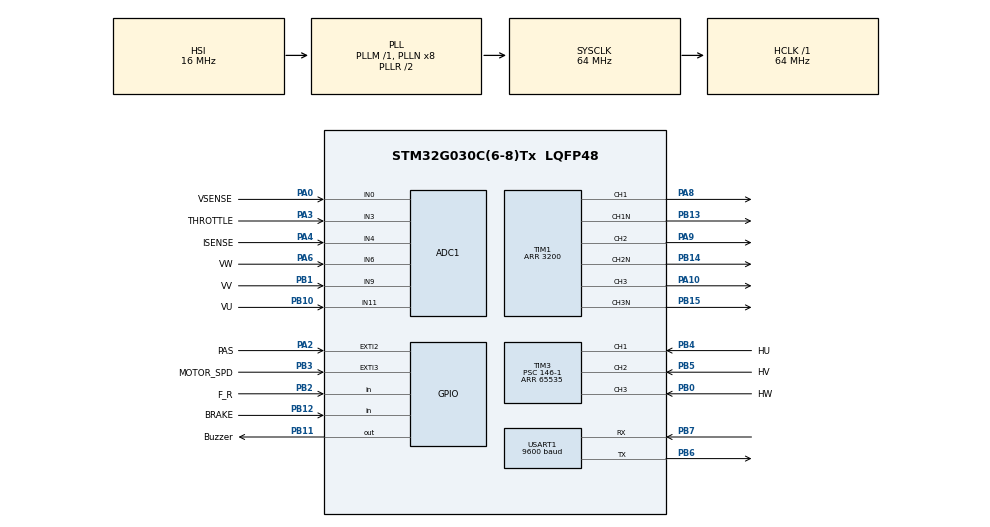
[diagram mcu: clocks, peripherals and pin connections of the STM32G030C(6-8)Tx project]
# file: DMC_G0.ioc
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ADC1.Channel-2\#ChannelRegularConversion=ADC_CHANNEL_3
ADC1.Channel-3\#ChannelRegularConversion=ADC_CHANNEL_4
ADC1.Channel-4\#ChannelRegularConversion=ADC_CHANNEL_0
ADC1.Channel-5\#ChannelRegularConversion=ADC_CHANNEL_TEMPSENSOR
ADC1.ContinuousConvMode=ENABLE
ADC1.DMAContinuousRequests=ENABLE
ADC1.NbrOfConversion=4
ADC1.NbrOfConversionFlag=1
ADC1.Rank-2\#ChannelRegularConversion=1
ADC1.Rank-3\#ChannelRegularConversion=2
ADC1.Rank-4\#ChannelRegularConversion=3
ADC1.Rank-5\#ChannelRegularConversion=4
ADC1.SamplingTime-2\#ChannelRegularConversion=ADC_SAMPLINGTIME_COMMON_1
ADC1.SamplingTime-3\#ChannelRegularConversion=ADC_SAMPLINGTIME_COMMON_1
ADC1.SamplingTime-4\#ChannelRegularConversion=ADC_SAMPLINGTIME_COMMON_1
ADC1.SamplingTime-5\#ChannelRegularConversion=ADC_SAMPLINGTIME_COMMON_1
ADC1.SamplingTimeCommon1=ADC_SAMPLETIME_160CYCLES_5
ADC1.SamplingTimeCommon2=ADC_SAMPLETIME_79CYCLES_5
ADC1.SelectedChannel=ADC_CHANNEL_0|ADC_CHANNEL_3|ADC_CHANNEL_4|ADC_CHANNEL_6|ADC_CHANNEL_TEMPSENSOR|ADC_CHANNEL_9|ADC_CHANNEL_11
ADC1.master=1
Dma.ADC1.0.Direction=DMA_PERIPH_TO_MEMORY
Dma.ADC1.0.EventEnable=DISABLE
Dma.ADC1.0.Instance=DMA1_Channel1
Dma.ADC1.0.MemDataAlignment=DMA_MDATAALIGN_WORD
Dma.ADC1.0.MemInc=DMA_MINC_ENABLE
Dma.ADC1.0.Mode=DMA_CIRCULAR
Dma.ADC1.0.PeriphDataAlignment=DMA_PDATAALIGN_WORD
Dma.ADC1.0.PeriphInc=DMA_PINC_DISABLE
Dma.ADC1.0.Polarity=HAL_DMAMUX_REQ_GEN_RISING
Dma.ADC1.0.Priority=DMA_PRIORITY_LOW
Dma.ADC1.0.RequestNumber=1
Dma.ADC1.0.SignalID=NONE
Dma.ADC1.0.SyncEnable=DISABLE
Dma.ADC1.0.SyncPolarity=HAL_DMAMUX_SYNC_NO_EVENT
Dma.ADC1.0.SyncRequestNumber=1
Dma.ADC1.0.SyncSignalID=NONE
Dma.Request0=ADC1
IWDG.Prescaler=IWDG_PRESCALER_256
Mcu.Family=STM32G0
Mcu.Name=STM32G030C(6-8)Tx
Mcu.Package=LQFP48
NVIC.ADC1_IRQn=true\:0\:0\:false\:false\:true\:true\:true\:true
NVIC.DMA1_Channel1_IRQn=true\:0\:0\:false\:false\:true\:false\:true\:true
NVIC.EXTI2_3_IRQn=true\:0\:0\:false\:true\:true\:1\:true\:true\:true
NVIC.TIM14_IRQn=true\:0\:0\:false\:false\:true\:true\:true\:true
NVIC.TIM17_IRQn=true\:0\:0\:false\:false\:true\:true\:true\:true
NVIC.TIM1_BRK_UP_TRG_COM_IRQn=true\:0\:0\:false\:false\:true\:true\:true\:true
NVIC.TIM1_CC_IRQn=true\:0\:0\:false\:false\:true\:true\:true\:true
NVIC.TIM3_IRQn=true\:0\:0\:false\:false\:true\:true\:true\:true
NVIC.USART1_IRQn=true\:0\:0\:false\:false\:true\:true\:true\:true
PA0.GPIO_Label=VSENSE
PA0.Signal=SharedAnalog_PA0
PA10.Signal=S_TIM1_CH3
PA13.Mode=Serial_Wire
PA13.Signal=SYS_SWDIO
PA14-BOOT0.Mode=Serial_Wire
PA14-BOOT0.Signal=SYS_SWCLK
PA2.GPIO_Label=PAS
PA2.Signal=GPXTI2
PA3.GPIO_Label=THROTTLE
PA3.Signal=SharedAnalog_PA3
PA4.GPIO_Label=ISENSE
PA4.Signal=SharedAnalog_PA4
PA6.GPIO_Label=VW
PA6.Signal=SharedAnalog_PA6
PA8.Signal=S_TIM1_CH1
PA9.Signal=S_TIM1_CH2
PB0.GPIO_Label=HW
PB0.Signal=S_TIM3_CH3
PB1.GPIO_Label=VV
PB1.Signal=SharedAnalog_PB1
PB10.GPIO_Label=VU
PB10.Signal=SharedAnalog_PB10
PB11.GPIO_Label=Buzzer
PB11.GPIO_ModeDefaultOutputPP=GPIO_MODE_OUTPUT_PP
PB11.GPIO_PuPd=GPIO_PULLUP
PB11.Signal=GPIO_Output
PB12.GPIO_Label=BRAKE
PB12.Signal=GPIO_Input
PB13.Mode=PWM Generation1 CH1 CH1N
PB13.Signal=TIM1_CH1N
PB14.Mode=PWM Generation2 CH2 CH2N
PB14.Signal=TIM1_CH2N
PB15.Mode=PWM Generation3 CH3 CH3N
PB15.Signal=TIM1_CH3N
PB2.GPIO_Label=F_R
PB2.GPIO_PuPd=GPIO_PULLUP
PB2.Signal=GPIO_Input
PB3.GPIO_Label=MOTOR_SPD
PB3.Signal=GPXTI3
PB4.GPIO_Label=HU
PB4.Signal=S_TIM3_CH1
PB5.GPIO_Label=HV
PB5.Signal=S_TIM3_CH2
PB6.Mode=Asynchronous
PB6.Signal=USART1_TX
PB7.Mode=Asynchronous
PB7.Signal=USART1_RX
PF0-OSC_IN\ (PF0).Mode=HSE-External-Clock-Source
PF0-OSC_IN\ (PF0).Signal=RCC_OSC_IN
ProjectManager.HeapSize=0x200
ProjectManager.StackSize=0x400
ProjectManager.TargetToolchain=STM32CubeIDE
RCC.ADCFreq_Value=64000000
RCC.AHBFreq_Value=64000000
RCC.CortexFreq_Value=64000000
RCC.EXTERNAL_CLOCK_VALUE=12288000
RCC.HCLKFreq_Value=64000000
RCC.HSE_VALUE=8000000
RCC.HSI_VALUE=16000000
RCC.LSE_VALUE=32768
RCC.SYSCLKFreq_VALUE=64000000
RCC.SYSCLKSource=RCC_SYSCLKSOURCE_PLLCLK
RCC.VCOOutputFreq_Value=128000000
SH.S_TIM1_CH1.0=TIM1_CH1,PWM Generation1 CH1 CH1N
SH.S_TIM1_CH2.0=TIM1_CH2,PWM Generation2 CH2 CH2N
SH.S_TIM1_CH3.0=TIM1_CH3,PWM Generation3 CH3 CH3N
SH.S_TIM3_CH1.0=TIM3_CH1,Xored_Inputs_Hall_Sensor_Interface
SH.S_TIM3_CH2.0=TIM3_CH2,Xored_Inputs_Hall_Sensor_Interface
SH.S_TIM3_CH3.0=TIM3_CH3,Xored_Inputs_Hall_Sensor_Interface
SH.SharedAnalog_PA0.0=GPIO_Analog
SH.SharedAnalog_PA0.1=ADC1_IN0,IN0
SH.SharedAnalog_PA3.0=GPIO_Analog
SH.SharedAnalog_PA3.1=ADC1_IN3,IN3
SH.SharedAnalog_PA4.0=GPIO_Analog
SH.SharedAnalog_PA4.1=ADC1_IN4,IN4
SH.SharedAnalog_PA6.0=GPIO_Analog
SH.SharedAnalog_PA6.1=ADC1_IN6,IN6
SH.SharedAnalog_PB1.0=GPIO_Analog
SH.SharedAnalog_PB1.1=ADC1_IN9,IN9
SH.SharedAnalog_PB10.0=GPIO_Analog
SH.SharedAnalog_PB10.1=ADC1_IN11,IN11
TIM1.AutoReloadPreload=TIM_AUTORELOAD_PRELOAD_ENABLE
TIM1.Channel-PWM\ Generation1\ CH1\ CH1N=TIM_CHANNEL_1
TIM1.Channel-PWM\ Generation2\ CH2\ CH2N=TIM_CHANNEL_2
TIM1.Channel-PWM\ Generation3\ CH3\ CH3N=TIM_CHANNEL_3
TIM1.CounterMode=TIM_COUNTERMODE_CENTERALIGNED1
TIM1.DeadTime=130-1
TIM1.OCNPolarity_1=TIM_OCNPOLARITY_LOW
TIM1.OCNPolarity_2=TIM_OCNPOLARITY_LOW
TIM1.OCNPolarity_3=TIM_OCNPOLARITY_LOW
TIM1.OCPolarity_1=TIM_OCPOLARITY_LOW
TIM1.OCPolarity_2=TIM_OCPOLARITY_LOW
TIM1.OCPolarity_3=TIM_OCPOLARITY_LOW
TIM1.Period=3200
TIM14.Period=3200
TIM17.Prescaler=8
TIM3.AutoReloadPreload=TIM_AUTORELOAD_PRELOAD_DISABLE
TIM3.CounterMode=TIM_COUNTERMODE_UP
TIM3.IC1Filter=14
TIM3.Period=65535
TIM3.Prescaler=146-1
USART1.BaudRate=9600
USART1.VirtualMode-Asynchronous=VM_ASYNC
VP_ADC1_TempSens_Input.Mode=IN-TempSens
VP_IWDG_VS_IWDG.Mode=IWDG_Activate
VP_TIM14_VS_ClockSourceINT.Mode=Enable_Timer
VP_TIM17_VS_ClockSourceINT.Mode=Enable_Timer
VP_TIM1_VS_ClockSourceINT.Mode=Internal
VP_TIM3_VS_ClockSourceINT.Mode=Internal
board=custom

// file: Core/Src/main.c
/* USER CODE BEGIN Header */
/**
  ******************************************************************************
  * @file           : main.c
  * @brief          : Main program body
  ******************************************************************************
  * @attention
  *
  * Copyright (c) 2024 STMicroelectronics.
  * All rights reserved.
  *
  * This software is licensed under terms that can be found in the LICENSE file
  * in the root directory of this software component.
  * If no LICENSE file comes with this software, it is provided AS-IS.
  *
  ******************************************************************************
  */
/* USER CODE END Header */
#include "main.h"
#include "adc.h"
#include "dma.h"
#include "iwdg.h"
#include "tim.h"
#include "usart.h"
#include "gpio.h"

/* USER CODE BEGIN Includes */
#include "initialtask.h"

/* USER CODE END Includes */

void SystemClock_Config(void);
static void MX_NVIC_Init(void);

int main(void)
{

  /* MCU Configuration--------------------------------------------------------*/

  /* Reset of all peripherals, Initializes the Flash interface and the Systick. */
  HAL_Init();

  /* Configure the system clock */
  SystemClock_Config();

  /* Initialize all configured peripherals */
  MX_GPIO_Init();
  MX_DMA_Init();
  MX_ADC1_Init();
  MX_TIM1_Init();
  MX_TIM3_Init();
  MX_TIM14_Init();
  MX_TIM17_Init();
  MX_IWDG_Init();
  MX_USART1_UART_Init();

  /* Initialize interrupts */
  MX_NVIC_Init();
  /* USER CODE BEGIN 2 */
  InitalConfig();
  /* USER CODE END 2 */

  /* Infinite loop */
  while (1)
  {

    /* USER CODE BEGIN 3 */
	  HAL_IWDG_Refresh(&hiwdg);
  }
  /* USER CODE END 3 */
}

void SystemClock_Config(void)
{
  RCC_OscInitTypeDef RCC_OscInitStruct = {0};
  RCC_ClkInitTypeDef RCC_ClkInitStruct = {0};

  /** Configure the main internal regulator output voltage
  */
  HAL_PWREx_ControlVoltageScaling(PWR_REGULATOR_VOLTAGE_SCALE1);

  /** Initializes the RCC Oscillators according to the specified parameters
  * in the RCC_OscInitTypeDef structure.
  */
  RCC_OscInitStruct.OscillatorType = RCC_OSCILLATORTYPE_HSI|RCC_OSCILLATORTYPE_LSI;
  RCC_OscInitStruct.HSIState = RCC_HSI_ON;
  RCC_OscInitStruct.HSIDiv = RCC_HSI_DIV1;
  RCC_OscInitStruct.HSICalibrationValue = RCC_HSICALIBRATION_DEFAULT;
  RCC_OscInitStruct.LSIState = RCC_LSI_ON;
  RCC_OscInitStruct.PLL.PLLState = RCC_PLL_ON;
  RCC_OscInitStruct.PLL.PLLSource = RCC_PLLSOURCE_HSI;
  RCC_OscInitStruct.PLL.PLLM = RCC_PLLM_DIV1;
  RCC_OscInitStruct.PLL.PLLN = 8;
  RCC_OscInitStruct.PLL.PLLP = RCC_PLLP_DIV2;
  RCC_OscInitStruct.PLL.PLLR = RCC_PLLR_DIV2;
  if (HAL_RCC_OscConfig(&RCC_OscInitStruct) != HAL_OK)
  {
    Error_Handler();
  }

  /** Initializes the CPU, AHB and APB buses clocks
  */
  RCC_ClkInitStruct.ClockType = RCC_CLOCKTYPE_HCLK|RCC_CLOCKTYPE_SYSCLK
                              |RCC_CLOCKTYPE_PCLK1;
  RCC_ClkInitStruct.SYSCLKSource = RCC_SYSCLKSOURCE_PLLCLK;
  RCC_ClkInitStruct.AHBCLKDivider = RCC_SYSCLK_DIV1;
  RCC_ClkInitStruct.APB1CLKDivider = RCC_HCLK_DIV1;

  if (HAL_RCC_ClockConfig(&RCC_ClkInitStruct, FLASH_LATENCY_2) != HAL_OK)
  {
    Error_Handler();
  }
}

/**
  * @brief NVIC Configuration.
  * @retval None
  */
static void MX_NVIC_Init(void)
{
  /* EXTI2_3_IRQn interrupt configuration */
  HAL_NVIC_SetPriority(EXTI2_3_IRQn, 0, 0);
  HAL_NVIC_EnableIRQ(EXTI2_3_IRQn);
}

void Error_Handler(void)
{
  __disable_irq();
  while (1)
  {
  }
}
